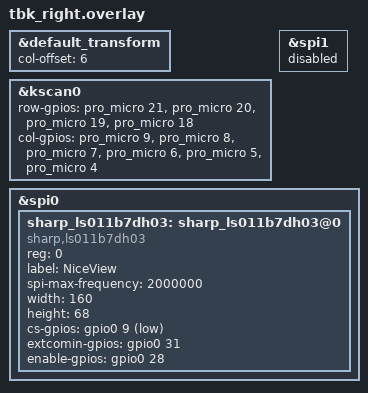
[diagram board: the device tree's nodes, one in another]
#include "tbk.dtsi"

&default_transform {
    col-offset = <6>;
};

&kscan0 {
	  row-gpios
        = <&pro_micro 21 (GPIO_ACTIVE_HIGH | GPIO_PULL_DOWN)>
        , <&pro_micro 20 (GPIO_ACTIVE_HIGH | GPIO_PULL_DOWN)>
        , <&pro_micro 19 (GPIO_ACTIVE_HIGH | GPIO_PULL_DOWN)>
        , <&pro_micro 18 (GPIO_ACTIVE_HIGH | GPIO_PULL_DOWN)>
        ; 
    col-gpios
        = <&pro_micro 9 (GPIO_ACTIVE_HIGH)>
        , <&pro_micro 8 (GPIO_ACTIVE_HIGH)>
        , <&pro_micro 7 (GPIO_ACTIVE_HIGH)>
        , <&pro_micro 6 (GPIO_ACTIVE_HIGH)>
        , <&pro_micro 5 (GPIO_ACTIVE_HIGH)>
        , <&pro_micro 4 (GPIO_ACTIVE_HIGH)>
        ;
};

&spi1 {
    status = "disabled";
};

&spi0 {
    status = "okay";

    sharp_ls011b7dh03: sharp_ls011b7dh03@0 {
        compatible = "sharp,ls011b7dh03";
        reg = <0>;
        label = "NiceView";

        spi-max-frequency = <2000000>;

        width  = <160>;
        height = <68>;

        cs-gpios       = <&gpio0 9 GPIO_ACTIVE_LOW>;
        extcomin-gpios = <&gpio0 31 GPIO_ACTIVE_HIGH>;
        enable-gpios   = <&gpio0 28 GPIO_ACTIVE_HIGH>;
    };
};
